# Polarfire SoC register map
Vendor: Microchip; File version: 1.0
CPU: Microchip PolarFire SoC 1.0, little endian
Registers are 32-bit, read-write, reset 0x0 unless marked. A register's access mark holds for its fields unless they carry their own. Offsets are from the block's base; [hi:lo] are bit positions; {n}, {i} and the like mark numbered series.

## GEM_A_LO (part 4 of 8) — GEM_A_LO Controller
Base 0x20110000
Same registers: GEM_B_LO 0x20112000, GEM_A_HI 0x28110000, GEM_B_HI 0x28112000
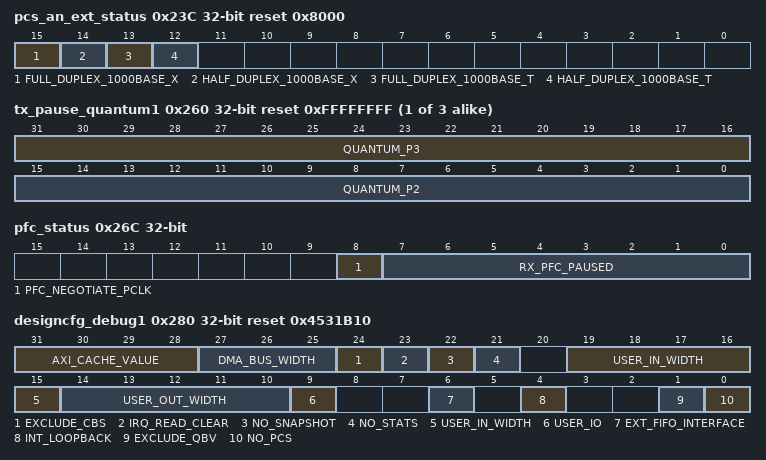
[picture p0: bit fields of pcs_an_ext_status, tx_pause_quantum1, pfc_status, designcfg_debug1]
0x23C pcs_an_ext_status ro reset 0x8000 — This register contains PCS auto-negotiation extended status information.
  [15] FULL_DUPLEX_1000BASE_X — Full duplex 1000BASE-X - hardwired to logic 1, indicates the GEM PCS can support full duplex operation of 1000BASE-X.
  [14] HALF_DUPLEX_1000BASE_X — half-duplex 1000BASE-X - hardwired to logic 0, indicates the GEM MAC cannot support half-duplex operation at gigabit speeds.
  [13] FULL_DUPLEX_1000BASE_T — Full duplex 1000BASE-T - hardwired to logic 0, indicates the GEM PCS cannot support 1000BASE-T full duplex operation.
  [12] HALF_DUPLEX_1000BASE_T — half-duplex 1000BASE-T - hardwired to logic 0, indicates the GEM PCS cannot support 1000BASE-T half-duplex operation.
{0x25C+4i} tx_pause_quantum{i} reset 0xFFFFFFFF (i=1..3) — Transmit Pause Quantum Register {i}
  [31:16] QUANTUM_P{2i+1} — Transmit pause quantum - written with the pause quantum value for pause frame transmission of priority {2i+1}.
  [15:0] QUANTUM_P{2i} — Transmit pause quantum - written with the pause quantum value for pause frame transmission of priority {2i}.
0x26C pfc_status ro — Priority Flow Control status register - indicates whether PFC has been negotiated and the current state of the PFC counters for each priority.
  [8] PFC_NEGOTIATE_PCLK — Set when PFC Priority Based Pause has been negotiated.
  [7:0] RX_PFC_PAUSED — Reflects the state of the rx_pfc_paused signals. Each bit in the vector corresponds to a priority indicated within the received PFC priority based pause frame. A bit is set when a PFC priority based pause frame has been received, and the associated priority pause time quantum is non-zero. The bit is cleared when the associated pause time has elapsed.
0x270 rx_lpi ro — Received LPI transitions
  [15:0] COUNT rw — Count of RX LPI transitions. A count of the number of times there is a transition from receiving normal idle to receiving low power idle. Cleared on read.
0x274 rx_lpi_time ro — Received LPI time
  [23:0] LPI_TIME rw — Time in LPI. This register increments once every 16 pclk cycles when the LPI indication bit 7 is set in the network status register. Cleared on read.
0x278 tx_lpi ro — Transmit LPI transitions
  [15:0] COUNT rw — Count of TX LPI transmissions. A count of the number of times the enable LPI transmission bit 19 goes from low to high in the network control register. Cleared on read.
0x27C tx_lpi_time ro — Transmit LPI time
  [23:0] LPI_TIME rw — Time in LPI. This register increments once every 16 pclk cycles when the enable LPI transmission bit 19 is set in the network control register. Cleared on read.
0x280 designcfg_debug1 ro reset 0x4531B10 — Design Configuration Register 1 - The GEM has many parameterisation options to configure the IP during compilation stage. This is achieved using Verilog define compiler directives in an include file called gem_defs.v. This configuration is readable through APB addressable designcfg_debug registers.
  [31:28] AXI_CACHE_VALUE — Takes the value of the edma_axi_awcache_value parameter which is set by the 'gem_axi_awcache_value DEFINE or will be zero if no packet buffer DMA is present
  [27:25] DMA_BUS_WIDTH — Takes the value of bits 7:5 of the 'gem_dma_bus_width DEFINE. So if the define is set to decimal 64 this will return binary 010.
  [24] EXCLUDE_CBS — Takes the value of the edma_exclude_cbs parameter which is set by the 'gem_exclude_cbs DEFINE.
  [23] IRQ_READ_CLEAR — Takes the value of the edma_irq_read_clear parameter which is set by the 'gem_irq_read_clear DEFINE
  [22] NO_SNAPSHOT — Takes the value of the edma_no_snapshot parameter which is set by the 'gem_no_snapshot DEFINE
  [21] NO_STATS — Takes the value of the edma_no_stats parameter which is set by the 'gem_no_stats DEFINE
  [19:15] USER_IN_WIDTH — Takes the value of the 'gem_user_in_width DEFINE or 1 if user_io not defined
  [14:10] USER_OUT_WIDTH — Takes the value of the 'gem_user_out_width DEFINE or 1 if user_io not defined
  [9] USER_IO — Takes the value of the 'gem_user_io DEFINE
  [6] EXT_FIFO_INTERFACE — Takes the value of the edma_ext_fifo_interface parameter which is set by the 'gem_ext_fifo_interface DEFINE
  [4] INT_LOOPBACK — Takes the value of the edma_int_loopback parameter which is set by the 'gem_int_loopback DEFINE
  [1] EXCLUDE_QBV — Takes the value of the edma_exclude_qbv parameter which is set by the 'gem_exclude_qbv DEFINE
  [0] NO_PCS — Takes the value of the edma_no_pcs parameter which is set by the 'gem_no_pcs DEFINE
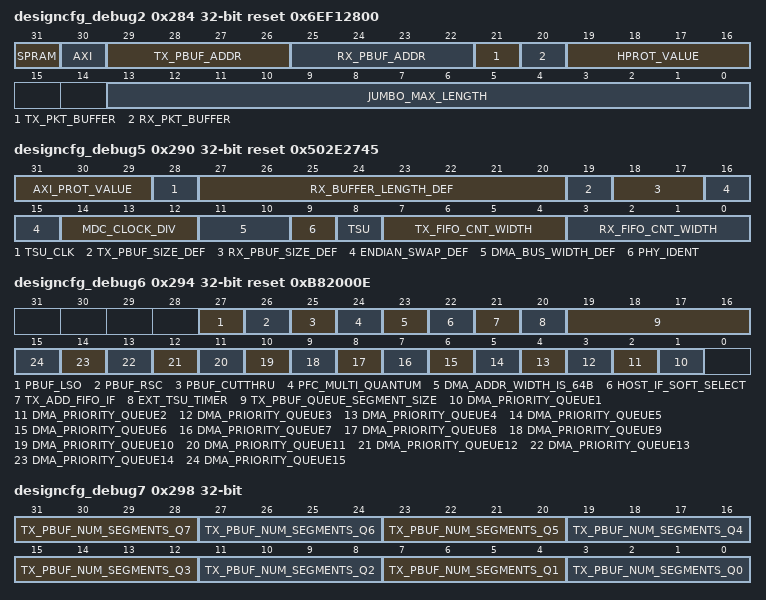
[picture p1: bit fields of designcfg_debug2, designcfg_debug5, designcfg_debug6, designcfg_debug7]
0x284 designcfg_debug2 ro reset 0x6EF12800 — Design Configuration Register 2
  [31] SPRAM — Takes the value of the edma_spram parameter which is set by the 'gem_spram DEFINE
  [30] AXI — Takes the value of the edma_axi parameter which is set by the 'gem_axi DEFINE but will be zero if the FIFO interface has been configured
  [29:26] TX_PBUF_ADDR — Takes the value of the 'gem_tx_pbuf_addr DEFINE or zero if pbuf_address is decimal 16
  [25:22] RX_PBUF_ADDR — Takes the value of the 'gem_rx_pbuf_addr DEFINE or zero if pbuf_address is decimal 16
  [21] TX_PKT_BUFFER — Takes the value of the edma_tx_pkt_buffer parameter which is set by the 'gem_tx_pkt_buffer DEFINE but will be zero if the FIFO interface has been configured
  [20] RX_PKT_BUFFER — Takes the value of the edma_rx_pkt_buffer parameter which is set by the 'gem_rx_pkt_buffer DEFINE but will be zero if the FIFO interface has been configured
  [19:16] HPROT_VALUE — Takes the value of the edma_hprot parameter which is set by the 'gem_hprot_value DEFINE
  [13:0] JUMBO_MAX_LENGTH — Takes the value of the edma_jumbo_max_length parameter which is set by the 'gem_jumbo_max_length DEFINE
0x288 designcfg_debug3 ro reset 0x4000000 — Design Configuration Register 3
  [29:24] NUM_SPEC_ADD_FILTERS — Takes the value of the 'num_spec_add_filters DEFINE
0x28C designcfg_debug4 ro — Design Configuration Register 4
0x290 designcfg_debug5 ro reset 0x502E2745 — Design Configuration Register 5
  [31:29] AXI_PROT_VALUE — Takes the value of the edma_axi_prot_value parameter which is set by the 'gem_axi_prot_value DEFINE but will be zero if the FIFO interface has been configured
  [28] TSU_CLK — Takes the value of the 'gem_tsu_clk DEFINE
  [27:20] RX_BUFFER_LENGTH_DEF — Takes the value of the 'gem_rx_buffer_length_def DEFINE
  [19] TX_PBUF_SIZE_DEF — Takes the value of the edma_tx_pbuf_size_def parameter which is set by the 'gem_tx_pbuf_size_def DEFINE but will be zero if the FIFO inteface has been configured
  [18:17] RX_PBUF_SIZE_DEF — Takes the value of the 'gem_rx_pbuf_size_def DEFINE
  [16:15] ENDIAN_SWAP_DEF — Takes the value of the 'gem_endian_swap_def DEFINE
  [14:12] MDC_CLOCK_DIV — Takes the value of the 'gem_mdc_clock_div DEFINE
  [11:10] DMA_BUS_WIDTH_DEF — Takes the value of the 'gem_dma_bus_width_def DEFINE
  [9] PHY_IDENT — Indicates whether the top and bottom PHY_ID registers are present in the address map
  [8] TSU — Takes the value of the 'gem_tsu DEFINE
  [7:4] TX_FIFO_CNT_WIDTH — Takes the value of the 'gem_tx_fifo_cnt_width DEFINE
  [3:0] RX_FIFO_CNT_WIDTH — Takes the value of the 'gem_rx_fifo_cnt_width DEFINE
0x294 designcfg_debug6 ro reset 0xB82000E — Design Configuration Register 6
  [27] PBUF_LSO — Takes the value of the edma_lso parameter which is set by the 'gem_pbuf_lso DEFINE this is zero if the FIFO interface or AHB is configured.
  [26] PBUF_RSC — Takes the value of the edma_rsc parameter which is set by the 'gem_pbuf_rsc DEFINE or is zero if the FIFO interface or AHB is configured.
  [25] PBUF_CUTTHRU — Takes the value of the 'gem_pbuf_cutthru DEFINE
  [24] PFC_MULTI_QUANTUM — Takes the value of the 'gem_pfc_multi_quantum DEFINE
  [23] DMA_ADDR_WIDTH_IS_64B — This is one if the 'gem_dma_addr_width DEFINE is set to 64.
  [22] HOST_IF_SOFT_SELECT — Takes the value of the 'gem_host_if_soft_select DEFINE
  [21] TX_ADD_FIFO_IF — Takes the value of the 'gem_tx_add_fifo_if DEFINE
  [20] EXT_TSU_TIMER — Takes the value of the 'gem_ext_tsu_timer DEFINE
  [19:16] TX_PBUF_QUEUE_SEGMENT_SIZE — Takes the value of the 'gem_tx_pbuf_queue_segment_size DEFINE
  [n] DMA_PRIORITY_QUEUE{n} (n=1..15) — Takes the value of the 'dma_priority_queue{n} DEFINE
0x298 designcfg_debug7 ro — Design Configuration Register 7
  [4n+3:4n] TX_PBUF_NUM_SEGMENTS_Q{n} (n=1..7) — Takes the value of the 'gem_tx_pbuf_num_segments_q{n} DEFINE
  [3:0] TX_PBUF_NUM_SEGMENTS_Q0 — Takes the value of the edma_tx_pbuf_num_segments_q0 parameter which is set by the 'gem_tx_pbuf_num_segments_q0 DEFINE or is zero if priority queuing is not configured.
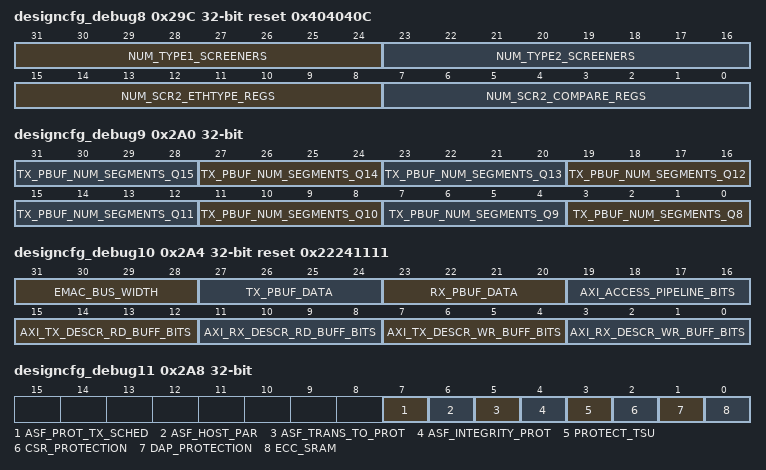
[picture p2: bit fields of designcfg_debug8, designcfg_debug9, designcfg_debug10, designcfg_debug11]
0x29C designcfg_debug8 ro reset 0x404040C — Design Configuration Register 8
  [31:24] NUM_TYPE1_SCREENERS — Takes the value of the 'num_type1_screeners DEFINE
  [23:16] NUM_TYPE2_SCREENERS — Takes the value of the 'num_type2_screeners DEFINE
  [15:8] NUM_SCR2_ETHTYPE_REGS — Takes the value of the 'num_scr2_ethtype_regs DEFINE
  [7:0] NUM_SCR2_COMPARE_REGS — Takes the value of the 'num_scr2_compare_regs DEFINE
0x2A0 designcfg_debug9 ro — Design Configuration Register 9
  [4n-29:4n-32] TX_PBUF_NUM_SEGMENTS_Q{n} (n=8..15) — Takes the value of the 'gem_tx_pbuf_num_segments_q{n} DEFINE
0x2A4 designcfg_debug10 ro reset 0x22241111 — Design Configuration Register 10
  [31:28] EMAC_BUS_WIDTH — Takes the value of the 'gem_emac_bus_width DEFINE. 1 - The MAC has a datawidth of 32bits. 2 - The MAC has a datawidth of 64bits. 4 - The MAC has a datawidth of 128bits
  [27:24] TX_PBUF_DATA — Takes the value of the 'gem_tx_pbuf_data DEFINE. 1 - The TX DPRAM has a datawidth of 32bits. 2 - The TX DPRAM has a datawidth of 64bits. 4 - The TX DPRAM has a datawidth of 128bits
  [23:20] RX_PBUF_DATA — Takes the value of the 'gem_rx_pbuf_data DEFINE. 1 - The RX DPRAM has a datawidth of 32bits. 2 - The RX DPRAM has a datawidth of 64bits. 4 - RX The DPRAM has a datawidth of 128bits
  [19:16] AXI_ACCESS_PIPELINE_BITS — Takes the value of the edma_axi_access_pipeline_bits parameter which is set by the 'gem_axi_access_pipeline_bits DEFINE or is zero if the FIFO interface is configured.
  [15:12] AXI_TX_DESCR_RD_BUFF_BITS — Takes the value of the edma_axi_tx_descr_rd_buff_bits parameter which is set by the 'gem_axi_tx_descr_rd_buff_bits DEFINE or is zero if the FIFO interface is configured.
  [11:8] AXI_RX_DESCR_RD_BUFF_BITS — Takes the value of the edma_axi_rx_descr_rd_buff_bits parameter which is set by the 'gem_axi_rx_descr_rd_buff_bits DEFINE or is zero if the FIFO interface is configured.
  [7:4] AXI_TX_DESCR_WR_BUFF_BITS — Takes the value of the edma_axi_tx_descr_wr_buff_bits parameter which is set by the 'gem_axi_tx_descr_wr_buff_bits DEFINE or is zero if the FIFO interface is configured.
  [3:0] AXI_RX_DESCR_WR_BUFF_BITS — Takes the value of the edma_axi_rx_descr_wr_buff_bits parameter which is set by the 'gem_axi_rx_descr_wr_buff_bits DEFINE or is zero if the FIFO interface is configured.
0x2A8 designcfg_debug11 ro — Design Configuration Register 11
  [7] ASF_PROT_TX_SCHED — Takes the value of the edma_asf_asf_prot_tx_sched parameter which is set by the 'gem_asf_prot_tx_sched DEFINE.
  [6] ASF_HOST_PAR — Takes the value of the edma_asf_host_par parameter which is set by the 'gem_asf_host_par DEFINE.
  [5] ASF_TRANS_TO_PROT — Takes the value of the edma_asf_trans_to_prot parameter which is set by the 'gem_asf_enable DEFINE.
  [4] ASF_INTEGRITY_PROT — Takes the value of the edma_asf_integrity_prot parameter which is set by the 'gem_asf_enable DEFINE.
  [3] PROTECT_TSU — akes the value of the edma_asf_prot_tsu parameter which is set by the 'gem_asf_prot_tsu DEFINE or is zero if no TSU is present.
  [2] CSR_PROTECTION — Takes the value of the edma_asf_csr_prot parameter which is set by the 'gem_asf_enable DEFINE.
  [1] DAP_PROTECTION — Takes the value of the edma_asf_dap_prot parameter which is set by the 'gem_asf_enable DEFINE.
  [0] ECC_SRAM — Takes the value of the edma_asf_ecc_sram parameter which is set by the 'gem_asf_ecc_sram DEFINE.
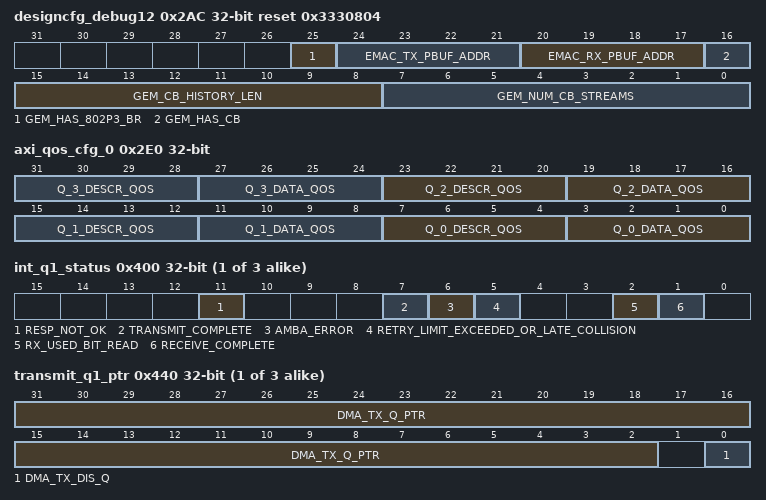
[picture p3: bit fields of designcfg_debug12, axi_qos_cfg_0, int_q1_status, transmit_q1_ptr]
0x2AC designcfg_debug12 ro reset 0x3330804 — Design Configuration Register 12
  [25] GEM_HAS_802P3_BR — Takes the value of the edma_has_br parameter which is set by the gem_has_802p3_br tick define. If defined the configuration contains both an express MAC (eMAC) and a pre-emptable MAC (pMAC) to allow 802.3br frame pre-emption.
  [24:21] EMAC_TX_PBUF_ADDR — Takes the value of the 'gem_emac_tx_pbuf_addr DEFINE - this defines the size of the transmit SRAM for express MAC (eMAC) when 802.3br is configured - will be zero if emac_tx_pbuf_address is decimal 16
  [20:17] EMAC_RX_PBUF_ADDR — Takes the value of the 'gem_emac_rx_pbuf_addr DEFINE - this defines the size of the receive SRAM for express MAC (eMAC) when 802.3br is configured - will be zero if emac_rx_pbuf_address is decimal 16
  [16] GEM_HAS_CB — Indicates whether gem has 802.1CB/FRER configured. This is zero if 'gem_no_of_cb_streams is undefined or zero.
  [15:8] GEM_CB_HISTORY_LEN — Takes the value of the 'gem_seq_history_len DEFINE or 0x01 if undefined.
  [7:0] GEM_NUM_CB_STREAMS — Takes the value of the 'gem_no_of_cb_streams DEFINE or 0x01 if undefined or the defined value is zero.
0x2E0 axi_qos_cfg_0 — AXI Quality of Service register 0. This register is only present if AXI is configured. This register contains 8-bits per queue to control driving of the ARQOS and AWQOS outputs (4-bits each). For each queue the lower four bits are for data accesses and the upper four bits are for descriptor accesses.
  [8n+7:8n+4] Q_{n}_DESCR_QOS (n=0..3) — Determines what value to drive to the ARQOS and AWQOS outputs (4-bits each) for queue {n} descriptor accesses.
  [8n+3:8n] Q_{n}_DATA_QOS (n=0..3) — Determines what value to drive to the ARQOS and AWQOS outputs (4-bits each) for queue {n} data accesses.
{0x3FC+4i} int_q{i}_status (i=1..3) — Priority Queue Interrupt Status Register
  [11] RESP_NOT_OK — bresp/hresp not OK
  [7] TRANSMIT_COMPLETE
  [6] AMBA_ERROR — Transmit frame corruption due to AMBA (AHB/AXI) error set if an error occurs whilst midway through reading transmit frame from the external memory, including HRESP errors(AHB), RRESP and BRESP errors (AXI) and buffers exhausted mid frame
  [5] RETRY_LIMIT_EXCEEDED_OR_LATE_COLLISION
  [2] RX_USED_BIT_READ
  [1] RECEIVE_COMPLETE
{0x43C+4i} transmit_q{i}_ptr (i=1..3) — This register holds the start address of the transmit buffer queue (transmit buffers descriptor list). The transmit buffer queue base address register must be initialized before transmit is started through bit 9 of the network control register. Once transmission has started, any write to the transmit buffer queue base address register is illegal and therefore ignored. Note that due to clock boundary synchronization, it takes a maximum of four pclk cycles from the writing of the transmit start bit before the transmitter is active. Writing to the transmit buffer queue base address register during this time may produce unpredictable results. Reading this register returns the location of the descriptor currently being accessed. Because the DMA can store data for multiple frames at once, this may not necessarily be pointing to the current frame being transmitted. In terms of AMBA AHB/AXI operation, the transmit descriptors are written to memory using a single 32bit AHB access. When the datapath is configured as 64bit or 128bit, the transmit descriptors should be aligned at 64-bit boundaries and each pair of 32-bit descriptors is read from memory using a single AHB/AXI access. For 32bit datapaths, the descriptors should be aligned at 32-bit boundaries and the descriptors are read from memory using two individual 32-bit non sequential accesses.
  [31:2] DMA_TX_Q_PTR — Transmit buffer queue base address - written with the address of the start of the transmit queue.
  [0] DMA_TX_DIS_Q — Disable queue if set to 1. This can be used to reduce the number of active queues and should only be changed while transmit is not enabled.
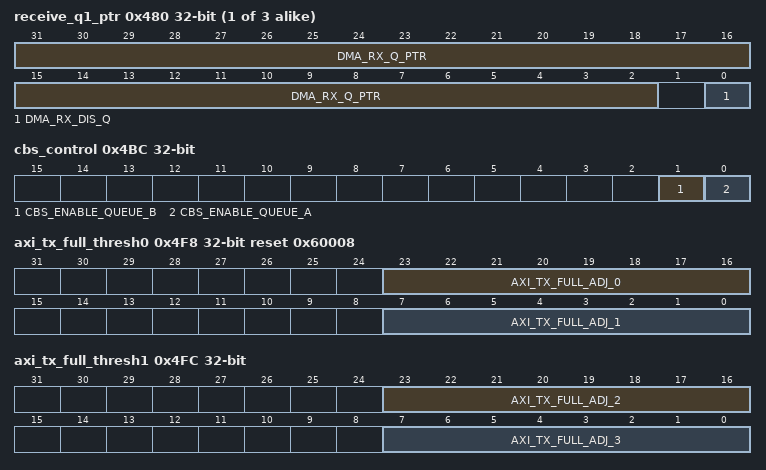
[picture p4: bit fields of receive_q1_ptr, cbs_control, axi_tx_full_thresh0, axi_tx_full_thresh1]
{0x47C+4i} receive_q{i}_ptr (i=1..3) — This register holds the start address of the receive buffer queue (receive buffers descriptor list). The receive buffer queue base address must be initialized before receive is enabled through bit 2 of the network control register. Once reception is enabled, any write to the receive buffer queue base address register is ignored. Reading this register returns the location of the descriptor currently being accessed. This value increments as buffers are used. Software should not use this register for determining where to remove received frames from the queue as it constantly changes as new frames are received. Software should instead work its way through the buffer descriptor queue checking the used bits. In terms of AMBA (AHB/AXI) operation, the receive descriptors are read from memory using a single 32bit AHB/AXI access. When the datapath is configured at 64bit or 128bit, the receive descriptors should be aligned at 64-bit boundaries and each pair of 32-bit descriptors is written to using a single 64bit AHB/AXI access. For 32bit datapaths, the receive descriptors should be aligned at 32-bit boundaries and are written to using two individual non sequential 32-bit accesses.
  [31:2] DMA_RX_Q_PTR — Receive buffer queue base address - written with the address of the start of the receive queue.
  [0] DMA_RX_DIS_Q — Disable queue if set to 1. This can be used to reduce the number of active queues and should only be changed while receive is not enabled.
{0x49C+4i} dma_rxbuf_size_q{i} reset 0x2 (i=1..3) — Receive Buffer Size
  [7:0] DMA_RX_Q_BUF_SIZE — DMA receive buffer size in system memory. The value defined by these bits determines the size of buffer to use in main system memory when writing received data. The value is defined in multiples of 64 bytes., :0x01 corresponds to buffers of 64 bytes., :0x02 corresponds to 128 bytes etc., :For example:, :0x02: 128 byte, :0x18: 1536 byte (1*max length frame/buffer), :0xA0: 10240 byte (1*10K jumbo frame/buffer), :0xFF: 16320 byte, :Note that this value should never be written as zero., :Note. The reset value of this field is equal to the gem_rx_buffer_length_def define, which is user configurable.
0x4BC cbs_control — The IdleSlope value is defined as the rate of change of credit when a packet is waiting to be sent. This must not exceed the portTransmitRate which is dependent on the speed of operation, eg, portTransmitRate: 1Gb/s = 32'h07735940 (125 Mbytes/s), 100Mb/sec = 32'h017D7840 (25 Mnibbles/s), 10Mb/sec = 32'h002625A0 (2.5 Mnibbles/s). If 50% of bandwidth was to be allocated to a particular queue in 1Gb/sec mode then the IdleSlope value for that queue would be calculated as 32'h07735940/2. Note: Credit-Based Shaping should be disabled prior to updating the IdleSlope values. As another example, for a 1722 audio packet with a payload of 6 samples per channel, the packet size would be: 7 (preamble) + 1 (SFD) + 50 (packet header) + 6x4x2(payload) + 4 (CRC) = 110 bytes. For a rate of 8000 packets per second, the desired rate would 110 x 8000 bytes per second, so the programmed idleSlope value would be 880000 for a 1Gb/s connection, or 1760000 for a 100Mb/s or 10Mbs connection. See Figure 6.3 in the IEEE 1722 standard. In practice, the actual transmission rate will be vary slightly from that calculated. In this case, the idleSlope value should be recalibrated based on the variance between the measured and expected rate, and in this case very accurate transmission rates can be achieved. (The idleslope value is scaled by 2.5 in 2.5G operation and so the port transmit rate is the same for 1G and 2.5G.)
  [1] CBS_ENABLE_QUEUE_B — Enable Credit-Based shaping on the 2nd highest priority queue (queue B). Write 1 to enable
  [0] CBS_ENABLE_QUEUE_A — Enable Credit-Based Shaping on the highest priority queue (queue A). Write 1 to enable
0x4C0 cbs_idleslope_q_a — Queue A is the highest priority queue. This is the highest indexed active queue, e.g. For a system with Q0 to Q7, this would be Q7 if all queues were active.
  [31:0] IDLESLOPE_A — IdleSlope value for queue A in bytes/sec for gigabit operation and nibbles/sec for 10/100 operation
0x4C4 cbs_idleslope_q_b — Queue B is the 2nd highest priority queue. This is the second highest indexed active queue, e.g. For a system with Q0 to Q7, this would be Q6 if all queues were active.
  [31:0] IDLESLOPE_B — IdleSlope value for queue B in bytes/sec for gigabit operation and nibbles/sec for 10/100 operation
0x4C8 upper_tx_q_base_addr — Upper 32 bits of transmit buffer descriptor queue base address.
  [31:0] UPPER_TX_Q_BASE_ADDR — Upper 32 bits of transmit buffer descriptor queue base address. Used when 64 bit addressing is enabled. (In releases earlier to 1p06f2 this register also affected the receive descriptor queue.)
0x4CC tx_bd_control — Transmit buffer descriptor control register - this register determines which transmit frames, with time stamps reported in the buffer descriptor status field in extended buffer descriptor mode, set bit 23 in transmit buffer descriptor word 1.
  [5:4] TX_BD_TS_MODE — Transmit Descriptor Timestamp Insertion mode - bit 23 in transmit buffer descriptor word 1 when extended buffer descriptor mode is enabled,, : 00: Bit 23 always zero,, : 01: Bit 23 high for PTP Event Frames only,, : 10: Bit 23 high for all PTP Frames only,, : 11: Bit 23 always high
0x4D0 rx_bd_control — Receive buffer descriptor control register - this register determines which receive frames have time stamps reported in the buffer descriptor status field
  [5:4] RX_BD_TS_MODE — Receive Descriptor Timestamp Insertion mode,, : 00: TS insertion disable,, : 01: TS inserted for PTP Event Frames only,, : 10: TS inserted for All PTP Frames only,, : 11: TS insertion for All Frames
0x4D4 upper_rx_q_base_addr — Upper 32 bits of receive buffer descriptor queue base address.
  [31:0] UPPER_RX_Q_BASE_ADDR — Upper 32 bits of receive buffer descriptor queue base address. Used when 64 bit addressing is enabled.
0x4EC wd_counter reset 0x7 — Hidden control register - do not alter
  [3:0] RX_BD_REREAD_TIMER — Controls counter used to retry receive descriptor reads (retries may occur if there was a resource error and there are frames waiting in the internal SRAM buffer to be off-loaded to host memory)
0x4F8 axi_tx_full_thresh0 reset 0x60008 — Hidden control register - do not alter
  [23:16] AXI_TX_FULL_ADJ_0 — AXI single port SRAM fine tuning
  [7:0] AXI_TX_FULL_ADJ_1 — AXI single port SRAM fine tuning
0x4FC axi_tx_full_thresh1 — Hidden control register - do not alter
  [23:16] AXI_TX_FULL_ADJ_2 — AXI single port SRAM fine tuning
  [7:0] AXI_TX_FULL_ADJ_3 — AXI single port SRAM fine tuning
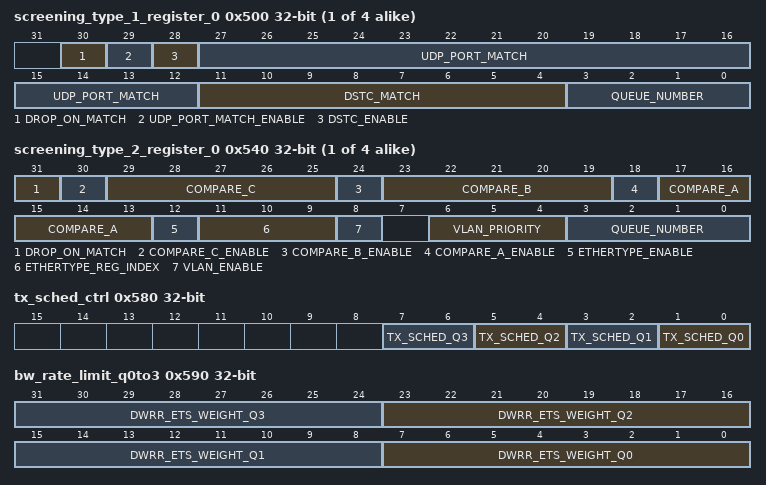
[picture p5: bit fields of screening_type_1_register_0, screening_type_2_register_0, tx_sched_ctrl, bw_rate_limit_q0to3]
{0x500+4i} screening_type_1_register_{i} (i=0..3) — Screening type 1 registers are used to allocate up to 16 priority queues to received frames based on certain IP or UDP fields of incoming frames. Firstly, when DS/TC match enable is set (bit 28), the DS (Differentiated Services) field of the received IPv4 header or TC field (traffic class) of IPv6 headers are matched against bits 11:4. Secondly, when UDP port match enable is set (bit 29), the UDP Destination Port of the received UDP frame is matched against bits 27:12. Both UDP and DS/TC matching can be enabled simultaneously or individually. If a match is successful, then the queue value programmed in bits 3:0 is allocated to the frame. The required number of Type 1 screening registers is configured in the gem defines file. Up to 16 type 1 screening registers have been allocated APB address space between 0x500 and 0x53C. The bit mappings for these registers are as follows:
  [30] DROP_ON_MATCH — When set, if the frame matches it will be completely dropped. In this case the queue number is don't care.
  [29] UDP_PORT_MATCH_ENABLE
  [28] DSTC_ENABLE
  [27:12] UDP_PORT_MATCH
  [11:4] DSTC_MATCH
  [3:0] QUEUE_NUMBER — Queue Number (0 to 15)
{0x540+4i} screening_type_2_register_{i} (i=0..3) — Screener Type 2 match registers allow a screen to be configured that is the combination of all or any of the following comparisons:, :1) An enabled VLAN Priority. A VLAN Priority match will be performed if the VLAN priority enable is set. The extracted priority field in the VLAN header is compared against 3 bits within the screener type 2 register itself., :2) An enabled EtherType., :3) An enabled Field Compare A. , :4) An enabled Field Compare B. , :5) An enabled Field Compare C. , :All enabled comparisons are ANDed together to form the overall type 2 screener match. If a match is successful, then the queue value programmed in bits 3:0 is allocated to the frame. The required number of Type 2 screening registers is configured in the gem defines file. Up to 16 type 2 screening registers have been allocated APB address space between 0x540 and 0x57C. The bit mappings for these registers are as follows:
  [31] DROP_ON_MATCH — When set, if the frame matches it will be completely dropped. In this case the queue number is don't care.
  [30] COMPARE_C_ENABLE
  [29:25] COMPARE_C — Compare C - Index to screener type 2 Compare register
  [24] COMPARE_B_ENABLE
  [23:19] COMPARE_B — Compare B - Index to screener type 2 Compare register
  [18] COMPARE_A_ENABLE
  [17:13] COMPARE_A — Compare A - Index to screener type 2 Compare register
  [12] ETHERTYPE_ENABLE
  [11:9] ETHERTYPE_REG_INDEX — Index to screener type 2 EtherType register
  [8] VLAN_ENABLE
  [6:4] VLAN_PRIORITY
  [3:0] QUEUE_NUMBER — Queue Number (0 to 15)
0x580 tx_sched_ctrl — This register controls the transmit scheduling algorithm the user can select for each active transmit queue. By default all queues are initialized to fixed priority, with the top indexed queue having overall priority.
  [2n+1:2n] TX_SCHED_Q{n} (n=0..3) — Queue {n} selection., : 00 : Fixed Priority, : 01 : CBS Enabled only valid for top two enabled queues and if CBS capability selected., : 10 : DWRR Enabled, : 11 : ETS Enabled
0x590 bw_rate_limit_q0to3 — This register holds the DWRR weighting value or the ETS bandwidth percentage value used by the transmit scheduler for queues 0 to 3.
  [8n+7:8n] DWRR_ETS_WEIGHT_Q{n} (n=0..3) — DWRR Weighting / ETS Bandwidth Allocation for queue {n}
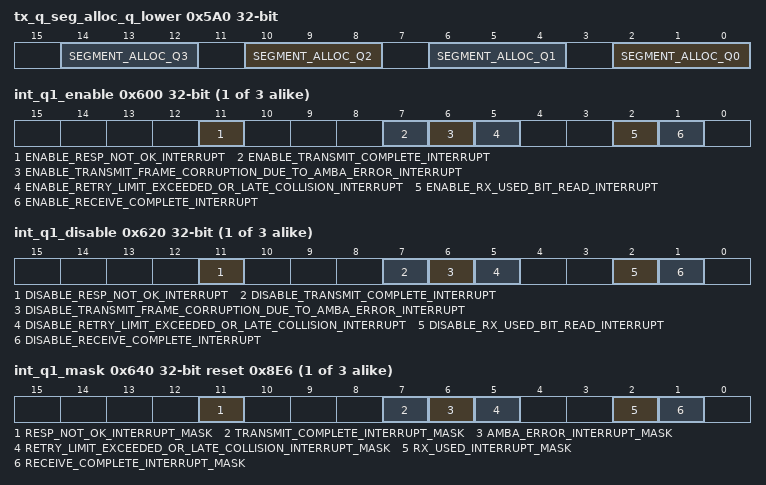
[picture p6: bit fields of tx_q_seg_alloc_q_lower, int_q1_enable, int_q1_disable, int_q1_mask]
0x5A0 tx_q_seg_alloc_q_lower — This register allows the user to distribute the Transmit SRAM used by the DMA across the priority queues, for queues 0 to 3. The SRAM itself is split into a number of evenly sized segments (this is defined in the verilog configuration defs file - for the configuration used to generate this register description, the total number of segments was set to '4'). Those segments can then be freely distributed across the active queues, in powers of 2. I.e. a value of 0 would mean 1 segment has been allocated to the queue. A value of 1 would mean 2 segments, a value of 2 means 4 segments and so on. The reset values of these registers are defined in the configuration defs file.
  [4n+2:4n] SEGMENT_ALLOC_Q{n} (n=0..3) — Number of segments allocated to q{n}. This should be entered as a log 2, for example entering a value of 2 would grant 4 segments. A maximum of 16 segments can be granted.
{0x5FC+4i} int_q{i}_enable (i=1..3) — At reset all interrupts are disabled. Writing a one to the relevant bit location enables the required interrupt. This register is write only and when read will return zero.
  [11] ENABLE_RESP_NOT_OK_INTERRUPT — Enable bresp/hresp not OK interrupt
  [7] ENABLE_TRANSMIT_COMPLETE_INTERRUPT
  [6] ENABLE_TRANSMIT_FRAME_CORRUPTION_DUE_TO_AMBA_ERROR_INTERRUPT — Enable Transmit frame corruption due to AMBA (AHB/AXI) error interrupt
  [5] ENABLE_RETRY_LIMIT_EXCEEDED_OR_LATE_COLLISION_INTERRUPT
  [2] ENABLE_RX_USED_BIT_READ_INTERRUPT
  [1] ENABLE_RECEIVE_COMPLETE_INTERRUPT
{0x61C+4i} int_q{i}_disable (i=1..3) — Writing a 1 to the relevant bit location disables that particular interrupt. This register is write only and when read will return zero.
  [11] DISABLE_RESP_NOT_OK_INTERRUPT — Disable bresp/hresp not OK interrupt
  [7] DISABLE_TRANSMIT_COMPLETE_INTERRUPT
  [6] DISABLE_TRANSMIT_FRAME_CORRUPTION_DUE_TO_AMBA_ERROR_INTERRUPT — Disable Transmit frame corruption due to AMBA (AHB/AXI) error interrupt
  [5] DISABLE_RETRY_LIMIT_EXCEEDED_OR_LATE_COLLISION_INTERRUPT
  [2] DISABLE_RX_USED_BIT_READ_INTERRUPT
  [1] DISABLE_RECEIVE_COMPLETE_INTERRUPT
{0x63C+4i} int_q{i}_mask ro reset 0x8E6 (i=1..3) — The interrupt mask register is a read only register indicating which interrupts are masked. All bits are set at reset and can be reset individually by writing to the interrupt enable register or set individually by writing to the interrupt disable register. Having separate address locations for enable and disable saves the need for performing a read modify write when updating the interrupt mask register. For test purposes there is a write-only function to this register that allows the bits in the interrupt status register to be set or cleared, regardless of the state of the mask register.
  [11] RESP_NOT_OK_INTERRUPT_MASK — bresp/hresp not OK interrupt mask., :0: Interrupt is enabled., :1: Interrupt is disabled., :A write to this register directly affects the state of the corresponding bit in the interrupt status register, causing an interrupt to be generated if a 1 is written.
  [7] TRANSMIT_COMPLETE_INTERRUPT_MASK — Transmit complete interrupt mask., :0: Interrupt is enabled., :1: Interrupt is disabled., :A write to this register directly affects the state of the corresponding bit in the interrupt status register, causing an interrupt to be generated if a 1 is written.
  [6] AMBA_ERROR_INTERRUPT_MASK — A read of this register returns the value of the AMBA (AHB/AXI) error interrupt mask., :0: Interrupt is enabled., :1: Interrupt is disabled., :A write to this register directly affects the state of the corresponding bit in the interrupt status register, causing an interrupt to be generated if a 1 is written.
  [5] RETRY_LIMIT_EXCEEDED_OR_LATE_COLLISION_INTERRUPT_MASK — retry limit exceeded or late collision interrupt mask., :0: Interrupt is enabled., :1: Interrupt is disabled., :A write to this register directly affects the state of the corresponding bit in the interrupt status register, causing an interrupt to be generated if a 1 is written.
  [2] RX_USED_INTERRUPT_MASK — A read of this register returns the value of the RX Used interrupt mask., :0: Interrupt is enabled., :1: Interrupt is disabled., :A write to this register directly affects the state of the corresponding bit in the interrupt status register, causing an interrupt to be generated if a 1 is written.
  [1] RECEIVE_COMPLETE_INTERRUPT_MASK — Receive complete interrupt mask., :0: Interrupt is enabled., :1: Interrupt is disabled., :A write to this register directly affects the state of the corresponding bit in the interrupt status register, causing an interrupt to be generated if a 1 is written.
{0x6E0+4i} screening_type_2_ethertype_reg_{i} (i=0..3) — EtherType Register
  [15:0] COMPARE_VALUE — EtherType compare value
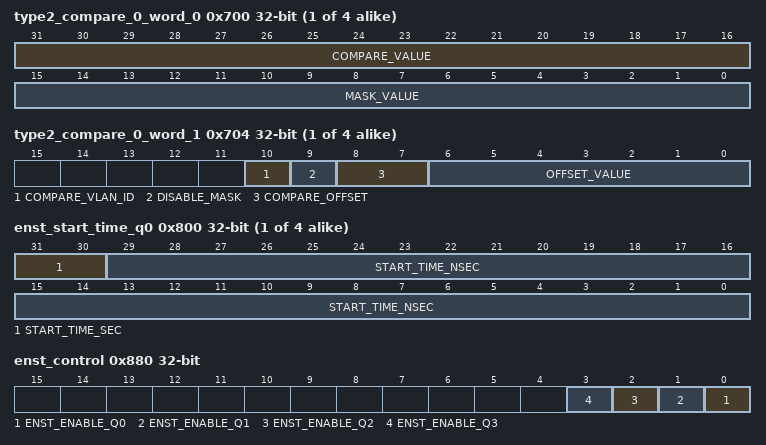
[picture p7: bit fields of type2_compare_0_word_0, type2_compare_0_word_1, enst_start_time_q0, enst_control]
{0x700+8i} type2_compare_{i}_word_0 (i=0..3) — Compare A, B and C fields of the screener type 2 match register are pointers to a pool of up to 32 compare registers. If enabled the compare is true if the data at the OFFSET into the frame, ANDed with the MASK Value if the mask is enabled, is equal to the COMPARE Value. Either a 16 bit comparison or a 32 bit comparison is done. This selection is made via the associated compare word1 register bit 9. If a 16 bit comparison is selected, then a 16 bit mask is also available to the user to select which bits should be compared. If the 32 bit compare option is selected, then no mask is available. The byte at the OFFSET number of bytes from the index start is compared thru bits 7:0 of the configured VALUE. The byte at the OFFSET number of bytes + 1 from the index start is compared thru bits 15:8 of the configured VALUE and so on. The OFFSET can be configured to be from 0 to 127 bytes from either the start of the frame, the byte following the therType field (last EtherType in the header if the frame is VLAN tagged), the byte following the IP header (IPv4 or IPv6) or from the byte following the start of the TCP/UDP header. The required number of Type 2 screening registers up to a maximum of 32 is configurable in the gem defines file and have been allocated APB address space between 0x700 and 0x7fc. Note. when using RX Partial Store and Forward mode and priority queues, the frame offset must be less than the Partial Store and Forward watermark. If the offset is higher than the watermark value it's not possible to identify the priority queue before the frame is sent to the AMBA interface, and an incorrect priority queue may be used.
  [31:16] COMPARE_VALUE — 2 byte Compare Value., :, :If bit 9 of the associated compare_word1 register is set, then the byte stored in bits [23:16] is compared against the byte in the received frame from the selected offset+2 and the byte stored in bits [31:24] is compared against the byte in the received frame from the selected offset+3., :, :If bit 9 of the associated compare_word1 register is clear, then the byte stored in bits [23:16] is compared against the byte in the received frame from the selected offset+0 and the byte stored in bits [31:24] is compared against the byte in the received frame from the selected offset+1., :
  [15:0] MASK_VALUE — These bits can be either a 2 byte mask field or an additional 2 byte Compare Value. , :, :If bit 9 of the associated compare_word1 register is set, then the byte stored in bits [7:0] is compared against the byte in the received frame from the selected offset+0 and the byte stored in bits [15:8] is compared against the byte in the received frame from the selected offset+1. , :, :If bit 9 of the associated compare_word1 register is clear, these bits become a direct 2-byte mask for the 2-byte compare register in bits [31:16]. A value of zero in a mask bit masks the corresponding data bit, a value of 1 enables the comparison.
{0x704+8i} type2_compare_{i}_word_1 (i=0..3) — Type2 Compare Word 1
  [10] COMPARE_VLAN_ID — If set bits 9, 8 and 6:0 must be 0 and bit 7 of compare_offset is used as follows:, :0 Compare C-TAG VID (VLAN has EtherType of 0x8100), :1 Compare S-TAG VID comparison (VLAN has EtherType of the value in the stacked VLAN register at 0x00C0), :Note the byte order is such that if 81 00 00 20 is received to indicate a C-TAG frame with VID 020 0x00200FFF would be written to the compare register. So in the special case of VLAN comparison the last byte received is the least significant byte in the compare register
  [9] DISABLE_MASK — This bit is used to control whether the compare register word_0 contains a 4-byte compare value, or a 2-byte compare value with a 2-byte mask value., :1 - 4-byte compare value, :0 - 2-byte compare, 2-byte mask
  [8:7] COMPARE_OFFSET — Compare byte offset., :00 : Offset from beginning of the frame., :01 : Offset from byte after Ether Type., :10 : Offset from byte following end of IP header., :11 : Offset from byte following end of TCP/UDP header
  [6:0] OFFSET_VALUE — Offset value in bytes
{0x800+4i} enst_start_time_q{i} (i=0..3) — This register sets the absolute time at which queue q{i} starts EnST transmit scheduling
  [31:30] START_TIME_SEC — Bits 31:30 of the start time (seconds field), for q{i}
  [29:0] START_TIME_NSEC — Bits 29:0 of the start time (nanoseconds field), for q{i}
{0x820+4i} enst_on_time_q{i} reset 0x1FFFF (i=0..3) — This register sets the time period for which queue q{i} is to be open, (on_time_nsec), this register has to be written according to the speed mode as:, : ||1Gbps or 2.5Gbps|| : on_time = on_time_nsec/8, : ||100Mbps|| : on_time = on_time_nsec/80, : ||10Mbps|| : on_time = on_time_nsec/800
  [16:0] ON_TIME — on_time, for q{i}
{0x840+4i} enst_off_time_q{i} (i=0..3) — This register sets the time period for which queue q{i} is to be blocked, (off_time_nsec), this register has to be written according to the speed mode as:, : ||1Gbps or 2.5Gbps|| => off_time = off_time_nsec/8, : ||100Mbps|| => off_time = off_time_nsec/80, : ||10Mbps|| => off_time = off_time_nsec/800
  [16:0] OFF_TIME — Off_time, for q{i}
0x880 enst_control — Enhancement for Scheduled Traffic control register. EnST scheduling can only be applied to a maximum number of 8 queues. If 802.3br operation has been configured and both an eMAC and pMAC are present then the eMAC only supports a single queue and EnST is enabled on the eMAC by writing to bit 0 of emac_enst_control.
  [n] ENST_ENABLE_Q{n} (n=0..3) — Set to enable enhanced scheduler traffic (ENST), for q{n}
0x8A0 frer_timeout — FRER timeout register. This determines when the sequence recovery reset timers are reset and is used by all of the configured CB streams. It is programmed as a count of 8192 rx_clk periods. 8192 rx_clk periods is 65.536 microseconds at gigabit speeds and 327.68 microseconds at 100M speeds, this allows a max timeout value of about 4 seconds at gigabit speeds - for test purposes if bit 12 (retry_test) is set in the network configuration register at 0x004 then the timeout value just becomes a count of rx_clk periods (ie a speed-up of 8192 in the time-out process).
  [15:0] TIMEOUT — Count of 8192 rx_clk periods.
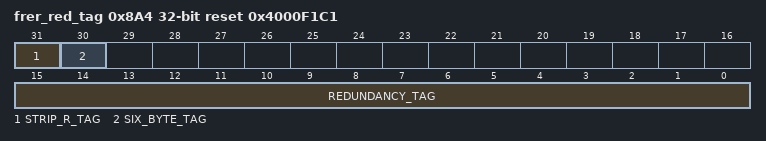
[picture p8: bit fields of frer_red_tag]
0x8A4 frer_red_tag reset 0x4000F1C1 — FRER redundancy tag register. This defines the Ethertype used to identify the R-TAG (redundancy tag) and contains a control bit to enable stripping of the R-TAG from received frames. IEEE 802.1CB has defined the value of this Ethertype to be 0xF1C1. Whether or not a particular stream uses the redundancy tag to locate the sequence number is determined by bit 28 in that streams control register.
  [31] STRIP_R_TAG — If set the redundancy tag is stripped from received frames. If this bit is set then the receive octet counters reflect post deletion frame size so the FRER functionality is transparent to higher level management if the stripping function is enabled. If the statistics counters need to reflect the actual number of octets received, then the stripping functionality should be disabled.
  [30] SIX_BYTE_TAG — Draft 2.4 and earlier drafts of the 802.1CB standard defined a four-byte redundancy tag. Drafts 2.5 and later specified a six-byte tag. Releases 1p10 and 1p11 were implemented in accordance with draft 2.4 of the standard. Set this bit to zero to inter-operate with implementations that use a four-byte tag.
  [15:0] REDUNDANCY_TAG — Ethertype value used to identify the redundancy tag (R-TAG).
